AUTOSAR XML (schema 4-2-2)
package /STELLANTIS/EPT/ASWCs
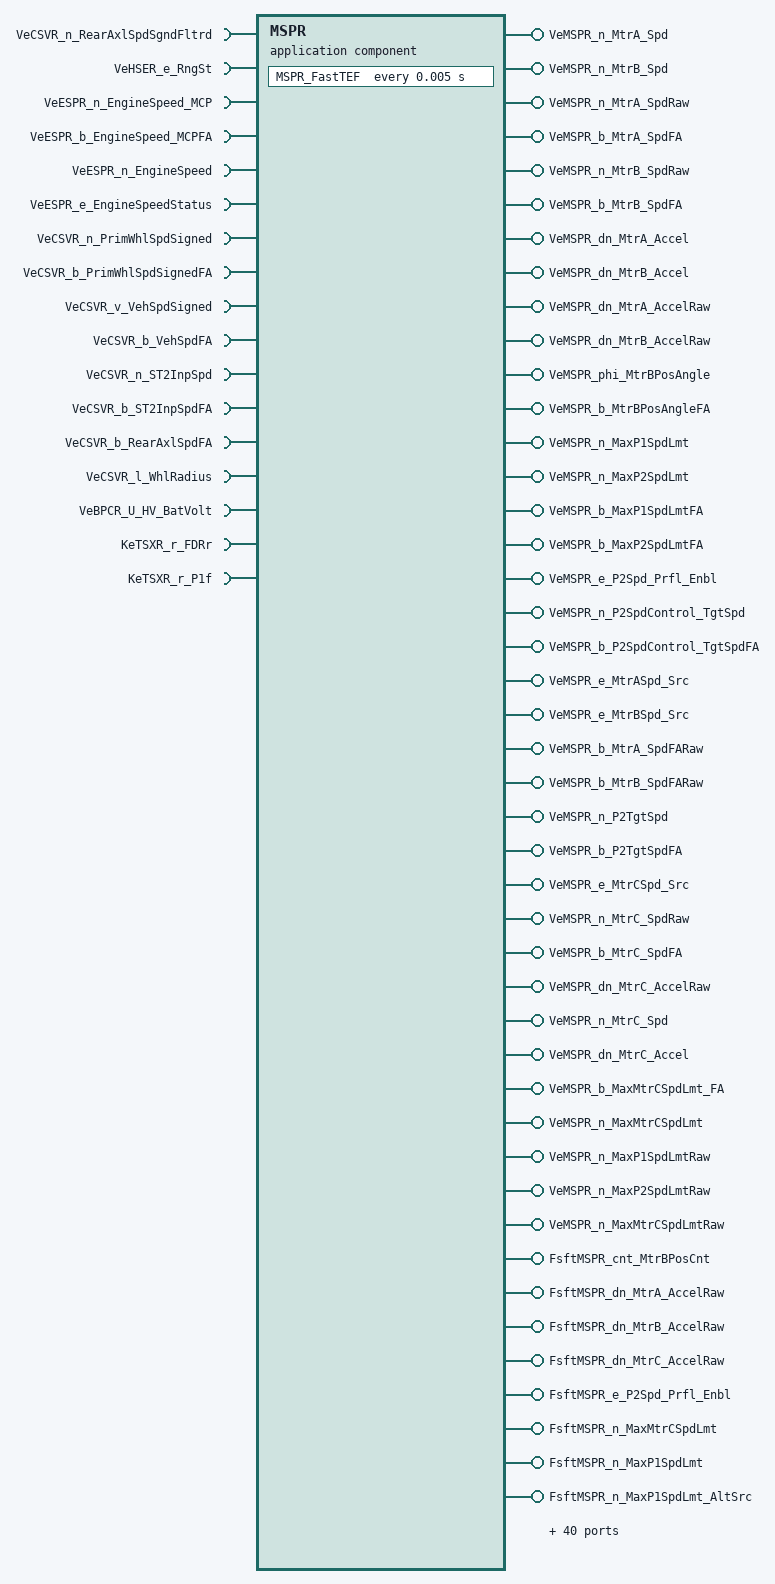
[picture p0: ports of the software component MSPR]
  application sw component type MSPR
    15 x require port:
      VeCSVR_n_RearAxlSpdSgndFltrd: nonqueued-receiver-com-spec{data-element=Value, init-value=0}, required-interface=VeCSVR_n_RearAxlSpdSgndFltrd
      VeHSER_e_RngSt: nonqueued-receiver-com-spec{data-element=Value, init-value=CeHSER_e_Init}, required-interface=VeHSER_e_RngSt
      VeESPR_n_EngineSpeed_MCP: nonqueued-receiver-com-spec{data-element=Value, init-value=0}, required-interface=VeESPR_n_EngineSpeed_MCP
      VeESPR_b_EngineSpeed_MCPFA: nonqueued-receiver-com-spec{data-element=Value, init-value=0}, required-interface=VeESPR_b_EngineSpeed_MCPFA
      VeESPR_n_EngineSpeed: nonqueued-receiver-com-spec{data-element=Value, init-value=0}, required-interface=VeESPR_n_EngineSpeed
      VeESPR_e_EngineSpeedStatus: nonqueued-receiver-com-spec{data-element=Value, init-value=CeESPR_e_EngSpdNormal}, required-interface=VeESPR_e_EngineSpeedStatus
      VeCSVR_n_PrimWhlSpdSigned: nonqueued-receiver-com-spec{data-element=Value, init-value=0}, required-interface=VeCSVR_n_PrimWhlSpdSigned
      VeCSVR_b_PrimWhlSpdSignedFA: nonqueued-receiver-com-spec{data-element=Value, init-value=0}, required-interface=VeCSVR_b_PrimWhlSpdSignedFA
      VeCSVR_v_VehSpdSigned: nonqueued-receiver-com-spec{data-element=Value, init-value=0}, required-interface=VeCSVR_v_VehSpdSigned
      VeCSVR_b_VehSpdFA: nonqueued-receiver-com-spec{data-element=Value, init-value=0}, required-interface=VeCSVR_b_VehSpdFA
      VeCSVR_n_ST2InpSpd: nonqueued-receiver-com-spec{data-element=Value, init-value=0}, required-interface=VeCSVR_n_ST2InpSpd
      VeCSVR_b_ST2InpSpdFA: nonqueued-receiver-com-spec{data-element=Value, init-value=0}, required-interface=VeCSVR_b_ST2InpSpdFA
      VeCSVR_b_RearAxlSpdFA: nonqueued-receiver-com-spec{data-element=Value, init-value=0}, required-interface=VeCSVR_b_RearAxlSpdFA
      VeCSVR_l_WhlRadius: nonqueued-receiver-com-spec{data-element=Value, init-value=0}, required-interface=VeCSVR_l_WhlRadius
      VeBPCR_U_HV_BatVolt: nonqueued-receiver-com-spec{data-element=Value, init-value=0}, required-interface=VeBPCR_U_HV_BatVolt
    84 x provide port:
      VeMSPR_n_MtrA_Spd: nonqueued-sender-com-spec{data-element=Value, init-value=0}, provided-interface=VeMSPR_n_MtrA_Spd
      VeMSPR_n_MtrB_Spd: nonqueued-sender-com-spec{data-element=Value, init-value=0}, provided-interface=VeMSPR_n_MtrB_Spd
      VeMSPR_n_MtrA_SpdRaw: nonqueued-sender-com-spec{data-element=Value, init-value=0}, provided-interface=VeMSPR_n_MtrA_SpdRaw
      VeMSPR_b_MtrA_SpdFA: nonqueued-sender-com-spec{data-element=Value, init-value=0}, provided-interface=VeMSPR_b_MtrA_SpdFA
      VeMSPR_n_MtrB_SpdRaw: nonqueued-sender-com-spec{data-element=Value, init-value=0}, provided-interface=VeMSPR_n_MtrB_SpdRaw
      VeMSPR_b_MtrB_SpdFA: nonqueued-sender-com-spec{data-element=Value, init-value=0}, provided-interface=VeMSPR_b_MtrB_SpdFA
      VeMSPR_dn_MtrA_Accel: nonqueued-sender-com-spec{data-element=Value, init-value=0}, provided-interface=VeMSPR_dn_MtrA_Accel
      VeMSPR_dn_MtrB_Accel: nonqueued-sender-com-spec{data-element=Value, init-value=0}, provided-interface=VeMSPR_dn_MtrB_Accel
      VeMSPR_dn_MtrA_AccelRaw: nonqueued-sender-com-spec{data-element=Value, init-value=0}, provided-interface=VeMSPR_dn_MtrA_AccelRaw
      VeMSPR_dn_MtrB_AccelRaw: nonqueued-sender-com-spec{data-element=Value, init-value=0}, provided-interface=VeMSPR_dn_MtrB_AccelRaw
      VeMSPR_phi_MtrBPosAngle: nonqueued-sender-com-spec{data-element=Value, init-value=0}, provided-interface=VeMSPR_phi_MtrBPosAngle
      VeMSPR_b_MtrBPosAngleFA: nonqueued-sender-com-spec{data-element=Value, init-value=0}, provided-interface=VeMSPR_b_MtrBPosAngleFA
      VeMSPR_n_MaxP1SpdLmt: nonqueued-sender-com-spec{data-element=Value, init-value=0}, provided-interface=VeMSPR_n_MaxP1SpdLmt
      VeMSPR_n_MaxP2SpdLmt: nonqueued-sender-com-spec{data-element=Value, init-value=0}, provided-interface=VeMSPR_n_MaxP2SpdLmt
      VeMSPR_b_MaxP1SpdLmtFA: nonqueued-sender-com-spec{data-element=Value, init-value=0}, provided-interface=VeMSPR_b_MaxP1SpdLmtFA
      VeMSPR_b_MaxP2SpdLmtFA: nonqueued-sender-com-spec{data-element=Value, init-value=0}, provided-interface=VeMSPR_b_MaxP2SpdLmtFA
      VeMSPR_e_P2Spd_Prfl_Enbl: nonqueued-sender-com-spec{data-element=Value, init-value=CeMSPR_e_P2Spd_Prfl_Not_Enbl}, provided-interface=VeMSPR_e_P2Spd_Prfl_Enbl
      VeMSPR_n_P2SpdControl_TgtSpd: nonqueued-sender-com-spec{data-element=Value, init-value=0}, provided-interface=VeMSPR_n_P2SpdControl_TgtSpd
      VeMSPR_b_P2SpdControl_TgtSpdFA: nonqueued-sender-com-spec{data-element=Value, init-value=0}, provided-interface=VeMSPR_b_P2SpdControl_TgtSpdFA
      VeMSPR_e_MtrASpd_Src: nonqueued-sender-com-spec{data-element=Value, init-value=CeMSPR_e_MtrSpSrc_MCP}, provided-interface=VeMSPR_e_MtrASpd_Src
      VeMSPR_e_MtrBSpd_Src: nonqueued-sender-com-spec{data-element=Value, init-value=CeMSPR_e_MtrSpSrc_MCP}, provided-interface=VeMSPR_e_MtrBSpd_Src
      VeMSPR_b_MtrA_SpdFARaw: nonqueued-sender-com-spec{data-element=Value, init-value=0}, provided-interface=VeMSPR_b_MtrA_SpdFARaw
      VeMSPR_b_MtrB_SpdFARaw: nonqueued-sender-com-spec{data-element=Value, init-value=0}, provided-interface=VeMSPR_b_MtrB_SpdFARaw
      VeMSPR_n_P2TgtSpd: nonqueued-sender-com-spec{data-element=Value, init-value=0}, provided-interface=VeMSPR_n_P2TgtSpd
      VeMSPR_b_P2TgtSpdFA: nonqueued-sender-com-spec{data-element=Value, init-value=0}, provided-interface=VeMSPR_b_P2TgtSpdFA
      VeMSPR_e_MtrCSpd_Src: nonqueued-sender-com-spec{data-element=Value, init-value=CeMSPR_e_MtrSpSrc_MCP}, provided-interface=VeMSPR_e_MtrCSpd_Src
      VeMSPR_n_MtrC_SpdRaw: nonqueued-sender-com-spec{data-element=Value, init-value=0}, provided-interface=VeMSPR_n_MtrC_SpdRaw
      VeMSPR_b_MtrC_SpdFA: nonqueued-sender-com-spec{data-element=Value, init-value=0}, provided-interface=VeMSPR_b_MtrC_SpdFA
      VeMSPR_dn_MtrC_AccelRaw: nonqueued-sender-com-spec{data-element=Value, init-value=0}, provided-interface=VeMSPR_dn_MtrC_AccelRaw
      VeMSPR_n_MtrC_Spd: nonqueued-sender-com-spec{data-element=Value, init-value=0}, provided-interface=VeMSPR_n_MtrC_Spd
      VeMSPR_dn_MtrC_Accel: nonqueued-sender-com-spec{data-element=Value, init-value=0}, provided-interface=VeMSPR_dn_MtrC_Accel
      VeMSPR_b_MaxMtrCSpdLmt_FA: nonqueued-sender-com-spec{data-element=Value, init-value=0}, provided-interface=VeMSPR_b_MaxMtrCSpdLmt_FA
      VeMSPR_n_MaxMtrCSpdLmt: nonqueued-sender-com-spec{data-element=Value, init-value=0}, provided-interface=VeMSPR_n_MaxMtrCSpdLmt
      VeMSPR_n_MaxP1SpdLmtRaw: nonqueued-sender-com-spec{data-element=Value, init-value=0}, provided-interface=VeMSPR_n_MaxP1SpdLmtRaw
      VeMSPR_n_MaxP2SpdLmtRaw: nonqueued-sender-com-spec{data-element=Value, init-value=0}, provided-interface=VeMSPR_n_MaxP2SpdLmtRaw
      VeMSPR_n_MaxMtrCSpdLmtRaw: nonqueued-sender-com-spec{data-element=Value, init-value=0}, provided-interface=VeMSPR_n_MaxMtrCSpdLmtRaw
      FsftMSPR_cnt_MtrBPosCnt: server-com-spec=FsftMSPR_cnt_MtrBPosCnt, provided-interface=FsftMSPR_cnt_MtrBPosCnt
      FsftMSPR_dn_MtrA_AccelRaw: server-com-spec=FsftMSPR_dn_MtrA_AccelRaw, provided-interface=FsftMSPR_dn_MtrA_AccelRaw
      FsftMSPR_dn_MtrB_AccelRaw: server-com-spec=FsftMSPR_dn_MtrB_AccelRaw, provided-interface=FsftMSPR_dn_MtrB_AccelRaw
      FsftMSPR_dn_MtrC_AccelRaw: server-com-spec=FsftMSPR_dn_MtrC_AccelRaw, provided-interface=FsftMSPR_dn_MtrC_AccelRaw
      FsftMSPR_e_P2Spd_Prfl_Enbl: server-com-spec=FsftMSPR_e_P2Spd_Prfl_Enbl, provided-interface=FsftMSPR_e_P2Spd_Prfl_Enbl
      FsftMSPR_n_MaxMtrCSpdLmt: server-com-spec=FsftMSPR_n_MaxMtrCSpdLmt, provided-interface=FsftMSPR_n_MaxMtrCSpdLmt
      FsftMSPR_n_MaxP1SpdLmt: server-com-spec=FsftMSPR_n_MaxP1SpdLmt, provided-interface=FsftMSPR_n_MaxP1SpdLmt
      FsftMSPR_n_MaxP1SpdLmt_AltSrc: server-com-spec=FsftMSPR_n_MaxP1SpdLmt_AltSrc, provided-interface=FsftMSPR_n_MaxP1SpdLmt_AltSrc
      FsftMSPR_n_MaxP2SpdLmt: server-com-spec=FsftMSPR_n_MaxP2SpdLmt, provided-interface=FsftMSPR_n_MaxP2SpdLmt
      FsftMSPR_n_MaxP2SpdLmt_AltSrc: server-com-spec=FsftMSPR_n_MaxP2SpdLmt_AltSrc, provided-interface=FsftMSPR_n_MaxP2SpdLmt_AltSrc
      FsftMSPR_n_MtrA_SpdRaw: server-com-spec=FsftMSPR_n_MtrA_SpdRaw, provided-interface=FsftMSPR_n_MtrA_SpdRaw
      FsftMSPR_n_MtrB_SpdRaw: server-com-spec=FsftMSPR_n_MtrB_SpdRaw, provided-interface=FsftMSPR_n_MtrB_SpdRaw
      FsftMSPR_n_MtrC_SpdRaw: server-com-spec=FsftMSPR_n_MtrC_SpdRaw, provided-interface=FsftMSPR_n_MtrC_SpdRaw
      FsftMSPR_n_P2SpdControl_TgtSpd: server-com-spec=FsftMSPR_n_P2SpdControl_TgtSpd, provided-interface=FsftMSPR_n_P2SpdControl_TgtSpd
      FsftMSPR_n_P2TgtSpd: server-com-spec=FsftMSPR_n_P2TgtSpd, provided-interface=FsftMSPR_n_P2TgtSpd
      FsftMSPR_t_MtrBTimeStamp: server-com-spec=FsftMSPR_t_MtrBTimeStamp, provided-interface=FsftMSPR_t_MtrBTimeStamp
      PokeMSPR_b_MCPA_TrqMntrWarn: server-com-spec{operation=PokeMSPR_b_MCPA_TrqMntrWarn, queue-length=1}, provided-interface=PokeMSPR_b_MCPA_TrqMntrWarn
      PokeMSPR_b_MCPB_TrqMntrWarn: server-com-spec{operation=PokeMSPR_b_MCPB_TrqMntrWarn, queue-length=1}, provided-interface=PokeMSPR_b_MCPB_TrqMntrWarn
      PokeMSPR_cnt_MtrBPosCnt: server-com-spec{operation=PokeMSPR_cnt_MtrBPosCnt, queue-length=1}, provided-interface=PokeMSPR_cnt_MtrBPosCnt
      PokeMSPR_dn_MtrA_AccelRaw: server-com-spec{operation=PokeMSPR_dn_MtrA_AccelRaw, queue-length=1}, provided-interface=PokeMSPR_dn_MtrA_AccelRaw
      PokeMSPR_dn_MtrB_AccelRaw: server-com-spec{operation=PokeMSPR_dn_MtrB_AccelRaw, queue-length=1}, provided-interface=PokeMSPR_dn_MtrB_AccelRaw
      PokeMSPR_dn_MtrC_AccelRaw: server-com-spec{operation=PokeMSPR_dn_MtrC_AccelRaw, queue-length=1}, provided-interface=PokeMSPR_dn_MtrC_AccelRaw
      PokeMSPR_e_P2Spd_Prfl_Enbl: server-com-spec{operation=PokeMSPR_e_P2Spd_Prfl_Enbl, queue-length=1}, provided-interface=PokeMSPR_e_P2Spd_Prfl_Enbl
      PokeMSPR_n_MaxMtrCSpdLmt: server-com-spec{operation=PokeMSPR_n_MaxMtrCSpdLmt, queue-length=1}, provided-interface=PokeMSPR_n_MaxMtrCSpdLmt
      PokeMSPR_n_MaxP1SpdLmt: server-com-spec{operation=PokeMSPR_n_MaxP1SpdLmt, queue-length=1}, provided-interface=PokeMSPR_n_MaxP1SpdLmt
      PokeMSPR_n_MaxP1SpdLmt_AltSrc: server-com-spec{operation=PokeMSPR_n_MaxP1SpdLmt_AltSrc, queue-length=1}, provided-interface=PokeMSPR_n_MaxP1SpdLmt_AltSrc
      PokeMSPR_n_MaxP2SpdLmt: server-com-spec{operation=PokeMSPR_n_MaxP2SpdLmt, queue-length=1}, provided-interface=PokeMSPR_n_MaxP2SpdLmt
      PokeMSPR_n_MaxP2SpdLmt_AltSrc: server-com-spec{operation=PokeMSPR_n_MaxP2SpdLmt_AltSrc, queue-length=1}, provided-interface=PokeMSPR_n_MaxP2SpdLmt_AltSrc
      PokeMSPR_n_MtrA_SpdRaw: server-com-spec{operation=PokeMSPR_n_MtrA_SpdRaw, queue-length=1}, provided-interface=PokeMSPR_n_MtrA_SpdRaw
      PokeMSPR_n_MtrB_SpdRaw: server-com-spec{operation=PokeMSPR_n_MtrB_SpdRaw, queue-length=1}, provided-interface=PokeMSPR_n_MtrB_SpdRaw
      PokeMSPR_n_MtrC_SpdRaw: server-com-spec{operation=PokeMSPR_n_MtrC_SpdRaw, queue-length=1}, provided-interface=PokeMSPR_n_MtrC_SpdRaw
      PokeMSPR_n_P2SpdControl_TgtSpd: server-com-spec{operation=PokeMSPR_n_P2SpdControl_TgtSpd, queue-length=1}, provided-interface=PokeMSPR_n_P2SpdControl_TgtSpd
      PokeMSPR_n_P2TgtSpd: server-com-spec{operation=PokeMSPR_n_P2TgtSpd, queue-length=1}, provided-interface=PokeMSPR_n_P2TgtSpd
      PokeMSPR_t_MtrBTimeStamp: server-com-spec{operation=PokeMSPR_t_MtrBTimeStamp, queue-length=1}, provided-interface=PokeMSPR_t_MtrBTimeStamp
      TmotMSPR_b_MCPA_TrqMntrWarn: server-com-spec=TmotMSPR_b_MCPA_TrqMntrWarn, provided-interface=TmotMSPR_b_MCPA_TrqMntrWarn
      TmotMSPR_b_MCPB_TrqMntrWarn: server-com-spec=TmotMSPR_b_MCPB_TrqMntrWarn, provided-interface=TmotMSPR_b_MCPB_TrqMntrWarn
      TmotMSPR_b_MtrA_AccelRaw: server-com-spec=TmotMSPR_b_MtrA_AccelRaw, provided-interface=TmotMSPR_b_MtrA_AccelRaw
      TmotMSPR_b_MtrA_SpdRaw: server-com-spec=TmotMSPR_b_MtrA_SpdRaw, provided-interface=TmotMSPR_b_MtrA_SpdRaw
      TmotMSPR_b_MtrB_AccelRaw: server-com-spec=TmotMSPR_b_MtrB_AccelRaw, provided-interface=TmotMSPR_b_MtrB_AccelRaw
      TmotMSPR_b_MtrB_SpdRaw: server-com-spec=TmotMSPR_b_MtrB_SpdRaw, provided-interface=TmotMSPR_b_MtrB_SpdRaw
      TmotMSPR_b_MtrC_AccelRaw: server-com-spec=TmotMSPR_b_MtrC_AccelRaw, provided-interface=TmotMSPR_b_MtrC_AccelRaw
      TmotMSPR_b_MtrC_SpdRaw: server-com-spec=TmotMSPR_b_MtrC_SpdRaw, provided-interface=TmotMSPR_b_MtrC_SpdRaw
      TmotMSPR_cnt_MtrBPosCnt: server-com-spec=TmotMSPR_cnt_MtrBPosCnt, provided-interface=TmotMSPR_cnt_MtrBPosCnt
      TmotMSPR_n_MaxMtrCSpdLmt: server-com-spec=TmotMSPR_n_MaxMtrCSpdLmt, provided-interface=TmotMSPR_n_MaxMtrCSpdLmt
      TmotMSPR_n_MaxP1SpdLmt: server-com-spec=TmotMSPR_n_MaxP1SpdLmt, provided-interface=TmotMSPR_n_MaxP1SpdLmt
      TmotMSPR_n_MaxP1SpdLmt_AltSrc: server-com-spec=TmotMSPR_n_MaxP1SpdLmt_AltSrc, provided-interface=TmotMSPR_n_MaxP1SpdLmt_AltSrc
      TmotMSPR_n_MaxP2SpdLmt: server-com-spec=TmotMSPR_n_MaxP2SpdLmt, provided-interface=TmotMSPR_n_MaxP2SpdLmt
      TmotMSPR_n_MaxP2SpdLmt_AltSrc: server-com-spec=TmotMSPR_n_MaxP2SpdLmt_AltSrc, provided-interface=TmotMSPR_n_MaxP2SpdLmt_AltSrc
    require port KeTSXR_r_FDRr: parameter-require-com-spec{init-value=KeTSXR_r_FDRr_KeTSXR_r_FDRr:11.1999998092651, parameter=KeTSXR_r_FDRr}, required-interface=KeTSXR_r_FDRr
    require port KeTSXR_r_P1f: parameter-require-com-spec{init-value=KeTSXR_r_P1f_KeTSXR_r_P1f:2.55550003051758, parameter=KeTSXR_r_P1f}, required-interface=KeTSXR_r_P1f
    behavior IB_MSPR: data-type-mapping=msADTtoIDTMapping, handle-termination-and-restart=NO-SUPPORT
      timing event Event_FastTEF: start-on-event=MSPR_FastTEF, period=0.005
      48 x operation invoked event:
        Event_FsftMSPR_cnt_MtrBPosCnt: start-on-event=FsftMSPR_cnt_MtrBPosCnt, operation=FsftMSPR_cnt_MtrBPosCnt.FsftMSPR_cnt_MtrBPosCnt
        Event_FsftMSPR_dn_MtrA_AccelRaw: start-on-event=FsftMSPR_dn_MtrA_AccelRaw, operation=FsftMSPR_dn_MtrA_AccelRaw.FsftMSPR_dn_MtrA_AccelRaw
        Event_FsftMSPR_dn_MtrB_AccelRaw: start-on-event=FsftMSPR_dn_MtrB_AccelRaw, operation=FsftMSPR_dn_MtrB_AccelRaw.FsftMSPR_dn_MtrB_AccelRaw
        Event_FsftMSPR_dn_MtrC_AccelRaw: start-on-event=FsftMSPR_dn_MtrC_AccelRaw, operation=FsftMSPR_dn_MtrC_AccelRaw.FsftMSPR_dn_MtrC_AccelRaw
        Event_FsftMSPR_e_P2Spd_Prfl_Enbl: start-on-event=FsftMSPR_e_P2Spd_Prfl_Enbl, operation=FsftMSPR_e_P2Spd_Prfl_Enbl.FsftMSPR_e_P2Spd_Prfl_Enbl
        Event_FsftMSPR_n_MaxMtrCSpdLmt: start-on-event=FsftMSPR_n_MaxMtrCSpdLmt, operation=FsftMSPR_n_MaxMtrCSpdLmt.FsftMSPR_n_MaxMtrCSpdLmt
        Event_FsftMSPR_n_MaxP1SpdLmt: start-on-event=FsftMSPR_n_MaxP1SpdLmt, operation=FsftMSPR_n_MaxP1SpdLmt.FsftMSPR_n_MaxP1SpdLmt
        Event_FsftMSPR_n_MaxP1SpdLmt_AltSrc: start-on-event=FsftMSPR_n_MaxP1SpdLmt_AltSrc, operation=FsftMSPR_n_MaxP1SpdLmt_AltSrc.FsftMSPR_n_MaxP1SpdLmt_AltSrc
        Event_FsftMSPR_n_MaxP2SpdLmt: start-on-event=FsftMSPR_n_MaxP2SpdLmt, operation=FsftMSPR_n_MaxP2SpdLmt.FsftMSPR_n_MaxP2SpdLmt
        Event_FsftMSPR_n_MaxP2SpdLmt_AltSrc: start-on-event=FsftMSPR_n_MaxP2SpdLmt_AltSrc, operation=FsftMSPR_n_MaxP2SpdLmt_AltSrc.FsftMSPR_n_MaxP2SpdLmt_AltSrc
        Event_FsftMSPR_n_MtrA_SpdRaw: start-on-event=FsftMSPR_n_MtrA_SpdRaw, operation=FsftMSPR_n_MtrA_SpdRaw.FsftMSPR_n_MtrA_SpdRaw
        Event_FsftMSPR_n_MtrB_SpdRaw: start-on-event=FsftMSPR_n_MtrB_SpdRaw, operation=FsftMSPR_n_MtrB_SpdRaw.FsftMSPR_n_MtrB_SpdRaw
        Event_FsftMSPR_n_MtrC_SpdRaw: start-on-event=FsftMSPR_n_MtrC_SpdRaw, operation=FsftMSPR_n_MtrC_SpdRaw.FsftMSPR_n_MtrC_SpdRaw
        Event_FsftMSPR_n_P2SpdControl_TgtSpd: start-on-event=FsftMSPR_n_P2SpdControl_TgtSpd, operation=FsftMSPR_n_P2SpdControl_TgtSpd.FsftMSPR_n_P2SpdControl_TgtSpd
        Event_FsftMSPR_n_P2TgtSpd: start-on-event=FsftMSPR_n_P2TgtSpd, operation=FsftMSPR_n_P2TgtSpd.FsftMSPR_n_P2TgtSpd
        Event_FsftMSPR_t_MtrBTimeStamp: start-on-event=FsftMSPR_t_MtrBTimeStamp, operation=FsftMSPR_t_MtrBTimeStamp.FsftMSPR_t_MtrBTimeStamp
        Event_PokeMSPR_b_MCPA_TrqMntrWarn: start-on-event=PokeMSPR_b_MCPA_TrqMntrWarn, operation=PokeMSPR_b_MCPA_TrqMntrWarn.PokeMSPR_b_MCPA_TrqMntrWarn
        Event_PokeMSPR_b_MCPB_TrqMntrWarn: start-on-event=PokeMSPR_b_MCPB_TrqMntrWarn, operation=PokeMSPR_b_MCPB_TrqMntrWarn.PokeMSPR_b_MCPB_TrqMntrWarn
        Event_PokeMSPR_cnt_MtrBPosCnt: start-on-event=PokeMSPR_cnt_MtrBPosCnt, operation=PokeMSPR_cnt_MtrBPosCnt.PokeMSPR_cnt_MtrBPosCnt
        Event_PokeMSPR_dn_MtrA_AccelRaw: start-on-event=PokeMSPR_dn_MtrA_AccelRaw, operation=PokeMSPR_dn_MtrA_AccelRaw.PokeMSPR_dn_MtrA_AccelRaw
        Event_PokeMSPR_dn_MtrB_AccelRaw: start-on-event=PokeMSPR_dn_MtrB_AccelRaw, operation=PokeMSPR_dn_MtrB_AccelRaw.PokeMSPR_dn_MtrB_AccelRaw
        Event_PokeMSPR_dn_MtrC_AccelRaw: start-on-event=PokeMSPR_dn_MtrC_AccelRaw, operation=PokeMSPR_dn_MtrC_AccelRaw.PokeMSPR_dn_MtrC_AccelRaw
        Event_PokeMSPR_e_P2Spd_Prfl_Enbl: start-on-event=PokeMSPR_e_P2Spd_Prfl_Enbl, operation=PokeMSPR_e_P2Spd_Prfl_Enbl.PokeMSPR_e_P2Spd_Prfl_Enbl
        Event_PokeMSPR_n_MaxMtrCSpdLmt: start-on-event=PokeMSPR_n_MaxMtrCSpdLmt, operation=PokeMSPR_n_MaxMtrCSpdLmt.PokeMSPR_n_MaxMtrCSpdLmt
        Event_PokeMSPR_n_MaxP1SpdLmt: start-on-event=PokeMSPR_n_MaxP1SpdLmt, operation=PokeMSPR_n_MaxP1SpdLmt.PokeMSPR_n_MaxP1SpdLmt
        Event_PokeMSPR_n_MaxP1SpdLmt_AltSrc: start-on-event=PokeMSPR_n_MaxP1SpdLmt_AltSrc, operation=PokeMSPR_n_MaxP1SpdLmt_AltSrc.PokeMSPR_n_MaxP1SpdLmt_AltSrc
        Event_PokeMSPR_n_MaxP2SpdLmt: start-on-event=PokeMSPR_n_MaxP2SpdLmt, operation=PokeMSPR_n_MaxP2SpdLmt.PokeMSPR_n_MaxP2SpdLmt
        Event_PokeMSPR_n_MaxP2SpdLmt_AltSrc: start-on-event=PokeMSPR_n_MaxP2SpdLmt_AltSrc, operation=PokeMSPR_n_MaxP2SpdLmt_AltSrc.PokeMSPR_n_MaxP2SpdLmt_AltSrc
        Event_PokeMSPR_n_MtrA_SpdRaw: start-on-event=PokeMSPR_n_MtrA_SpdRaw, operation=PokeMSPR_n_MtrA_SpdRaw.PokeMSPR_n_MtrA_SpdRaw
        Event_PokeMSPR_n_MtrB_SpdRaw: start-on-event=PokeMSPR_n_MtrB_SpdRaw, operation=PokeMSPR_n_MtrB_SpdRaw.PokeMSPR_n_MtrB_SpdRaw
        Event_PokeMSPR_n_MtrC_SpdRaw: start-on-event=PokeMSPR_n_MtrC_SpdRaw, operation=PokeMSPR_n_MtrC_SpdRaw.PokeMSPR_n_MtrC_SpdRaw
        Event_PokeMSPR_n_P2SpdControl_TgtSpd: start-on-event=PokeMSPR_n_P2SpdControl_TgtSpd, operation=PokeMSPR_n_P2SpdControl_TgtSpd.PokeMSPR_n_P2SpdControl_TgtSpd
        Event_PokeMSPR_n_P2TgtSpd: start-on-event=PokeMSPR_n_P2TgtSpd, operation=PokeMSPR_n_P2TgtSpd.PokeMSPR_n_P2TgtSpd
        Event_PokeMSPR_t_MtrBTimeStamp: start-on-event=PokeMSPR_t_MtrBTimeStamp, operation=PokeMSPR_t_MtrBTimeStamp.PokeMSPR_t_MtrBTimeStamp
        Event_TmotMSPR_b_MCPA_TrqMntrWarn: start-on-event=TmotMSPR_b_MCPA_TrqMntrWarn, operation=TmotMSPR_b_MCPA_TrqMntrWarn.TmotMSPR_b_MCPA_TrqMntrWarn
        Event_TmotMSPR_b_MCPB_TrqMntrWarn: start-on-event=TmotMSPR_b_MCPB_TrqMntrWarn, operation=TmotMSPR_b_MCPB_TrqMntrWarn.TmotMSPR_b_MCPB_TrqMntrWarn
        Event_TmotMSPR_b_MtrA_AccelRaw: start-on-event=TmotMSPR_b_MtrA_AccelRaw, operation=TmotMSPR_b_MtrA_AccelRaw.TmotMSPR_b_MtrA_AccelRaw
        Event_TmotMSPR_b_MtrA_SpdRaw: start-on-event=TmotMSPR_b_MtrA_SpdRaw, operation=TmotMSPR_b_MtrA_SpdRaw.TmotMSPR_b_MtrA_SpdRaw
        Event_TmotMSPR_b_MtrB_AccelRaw: start-on-event=TmotMSPR_b_MtrB_AccelRaw, operation=TmotMSPR_b_MtrB_AccelRaw.TmotMSPR_b_MtrB_AccelRaw
        Event_TmotMSPR_b_MtrB_SpdRaw: start-on-event=TmotMSPR_b_MtrB_SpdRaw, operation=TmotMSPR_b_MtrB_SpdRaw.TmotMSPR_b_MtrB_SpdRaw
        Event_TmotMSPR_b_MtrC_AccelRaw: start-on-event=TmotMSPR_b_MtrC_AccelRaw, operation=TmotMSPR_b_MtrC_AccelRaw.TmotMSPR_b_MtrC_AccelRaw
        Event_TmotMSPR_b_MtrC_SpdRaw: start-on-event=TmotMSPR_b_MtrC_SpdRaw, operation=TmotMSPR_b_MtrC_SpdRaw.TmotMSPR_b_MtrC_SpdRaw
        Event_TmotMSPR_cnt_MtrBPosCnt: start-on-event=TmotMSPR_cnt_MtrBPosCnt, operation=TmotMSPR_cnt_MtrBPosCnt.TmotMSPR_cnt_MtrBPosCnt
        Event_TmotMSPR_n_MaxMtrCSpdLmt: start-on-event=TmotMSPR_n_MaxMtrCSpdLmt, operation=TmotMSPR_n_MaxMtrCSpdLmt.TmotMSPR_n_MaxMtrCSpdLmt
        Event_TmotMSPR_n_MaxP1SpdLmt: start-on-event=TmotMSPR_n_MaxP1SpdLmt, operation=TmotMSPR_n_MaxP1SpdLmt.TmotMSPR_n_MaxP1SpdLmt
        Event_TmotMSPR_n_MaxP1SpdLmt_AltSrc: start-on-event=TmotMSPR_n_MaxP1SpdLmt_AltSrc, operation=TmotMSPR_n_MaxP1SpdLmt_AltSrc.TmotMSPR_n_MaxP1SpdLmt_AltSrc
        Event_TmotMSPR_n_MaxP2SpdLmt: start-on-event=TmotMSPR_n_MaxP2SpdLmt, operation=TmotMSPR_n_MaxP2SpdLmt.TmotMSPR_n_MaxP2SpdLmt
        Event_TmotMSPR_n_MaxP2SpdLmt_AltSrc: start-on-event=TmotMSPR_n_MaxP2SpdLmt_AltSrc, operation=TmotMSPR_n_MaxP2SpdLmt_AltSrc.TmotMSPR_n_MaxP2SpdLmt_AltSrc
      init event Event_MSPR_ac_Init: start-on-event=MSPR_ac_Init
      init event Event_PUP: start-on-event=MSPR_PUP
      init event Event_PwrOn: start-on-event=MSPR_PwrOn
      explicit-inter-runnable-variables:
        40 x data, all with category=VALUE, sw-calibration-access=READ-ONLY:
          VeMSPR_b_MtrA_SpdRawSgnl_Rcvd_write_IRV: type=Boolean, init-value=0
          VeMSPR_b_MtrA_AccelRaw_Rcvd_write_IRV: type=Boolean, init-value=0
          VeMSPR_dn_MtrA_AccelRaw_write_IRV: type=Float, init-value=0
          VeMSPR_b_MtrA_AccelRawFA_write_IRV: type=Boolean, init-value=0
          VeMSPR_b_MtrA_SpdRawFA_write_IRV: type=Boolean, init-value=0
          VeMSPR_n_MtrB_SpdRaw_Init_write_IRV: type=Float, init-value=0
          VeMSPR_b_MtrB_AccelRaw_Rcvd_write_IRV: type=Boolean, init-value=0
          VeMSPR_dn_MtrB_AccelRaw_write_IRV: type=Float, init-value=0
          VeMSPR_b_MtrB_AccelRawFA_write_IRV: type=Boolean, init-value=0
          VeMSPR_b_MtrB_SpdRawFA_write_IRV: type=Boolean, init-value=0
          VeMSPR_cnt_MtrBPosCntSgnl_Rcvd_write_IRV: type=Boolean, init-value=0
          VeMSPR_cnt_MtrBPosCnt_init_write_IRV: type=Float, init-value=0
          VeMSPR_n_MaxP1SpdLmt_AltSrcSgnl_Rcvd_write_IRV: type=Boolean, init-value=0
          VeMSPR_n_MaxP1SpdLmt_AltSrc_Init_write_IRV: type=Float, init-value=0
          VeMSPR_n_MaxP2SpdLmt_AltSrcSgnl_Rcvd_write_IRV: type=Boolean, init-value=0
          VeMSPR_n_MaxP2SpdLmt_AltSrc_Init_write_IRV: type=Float, init-value=0
          VeMSPR_b_MaxP1SpdLmtFA_write_IRV: type=Boolean, init-value=0
          VeMSPR_b_MaxP1SpdLmt_AltSrcFA_write_IRV: type=Boolean, init-value=0
          VeMSPR_b_MaxP2SpdLmtFA_write_IRV: type=Boolean, init-value=0
          VeMSPR_b_MaxP2SpdLmt_AltSrcFA_write_IRV: type=Boolean, init-value=0
          VeMSPR_n_MaxP2SpdLmtSgnl_Rcvd_write_IRV: type=Boolean, init-value=0
          VeMSPR_n_MaxP2SpdLmt_Init_write_IRV: type=Float, init-value=0
          VeMSPR_n_MaxP1SpdLmt_Init_write_IRV: type=Float, init-value=0
          VeMSPR_n_MaxP1SpdLmtSgnl_Rcvd_write_IRV: type=Boolean, init-value=0
          VeMSPR_n_MtrA_SpdRaw_Init_write_IRV: type=Float, init-value=0
          VeMSPR_b_MtrB_SpdRawSgnl_Rcvd_write_IRV: type=Boolean, init-value=0
          VeMSPR_dn_MtrC_AccelRaw_write_IRV: type=Float, init-value=0
          VeMSPR_b_MtrC_SpdRawFA_write_IRV: type=Boolean, init-value=0
          VeMSPR_n_MtrC_SpdRaw_Init_write_IRV: type=Float, init-value=0
          VeMSPR_b_MtrC_SpdRawSgnl_Rcvd_write_IRV: type=Boolean, init-value=0
          VeMSPR_b_MtrC_AccelRawFA_write_IRV: type=Boolean, init-value=0
          VeMSPR_b_MaxMtrCSpdLmtFA_write_IRV: type=Boolean, init-value=0
          VeMSPR_n_MaxMtrCSpdLmt_Init_write_IRV: type=Float, init-value=0
          VeMSPR_b_MaxMtrCSpdLmtSgnl_Rcvd_write_IRV: type=Boolean, init-value=0
          VeMSPR_b_MtrBPosCntFA_write_IRV: type=Boolean, init-value=0
          VeMSPR_e_P2Spd_Prfl_Enbl_write_IRV: type=TeMSPR_e_P2Spd_Prfl_Enbl, init-value=CeMSPR_e_P2Spd_Prfl_Not_Enbl
          VeMSPR_n_P2SpdControl_TgtSpd_Init_write_IRV: type=Float, init-value=0
          VeMSPR_b_P2SpdControl_TgtSpdFA_write_IRV: type=Boolean, init-value=0
          VeMSPR_n_P2TgtSpd_Init_write_IRV: type=Float, init-value=0
          VeMSPR_b_P2TgtSpdFA_write_IRV: type=Boolean, init-value=0
      52 x runnable:
        MSPR_ac_Init
          data-send-points:
            4 x access:
              OUT_VeMSPR_e_P2Spd_Prfl_Enbl_Value: accessed-variable=VeMSPR_e_P2Spd_Prfl_Enbl.Value
              OUT_VeMSPR_e_MtrASpd_Src_Value: accessed-variable=VeMSPR_e_MtrASpd_Src.Value
              OUT_VeMSPR_e_MtrBSpd_Src_Value: accessed-variable=VeMSPR_e_MtrBSpd_Src.Value
              OUT_VeMSPR_e_MtrCSpd_Src_Value: accessed-variable=VeMSPR_e_MtrCSpd_Src.Value
        MSPR_PUP
          data-send-points:
            9 x access:
              OUT_VeMSPR_n_MtrB_Spd_Value: accessed-variable=VeMSPR_n_MtrB_Spd.Value
              OUT_VeMSPR_n_MtrA_Spd_Value: accessed-variable=VeMSPR_n_MtrA_Spd.Value
              OUT_VeMSPR_dn_MtrB_Accel_Value: accessed-variable=VeMSPR_dn_MtrB_Accel.Value
              OUT_VeMSPR_dn_MtrA_Accel_Value: accessed-variable=VeMSPR_dn_MtrA_Accel.Value
              OUT_VeMSPR_dn_MtrC_Accel_Value: accessed-variable=VeMSPR_dn_MtrC_Accel.Value
              OUT_VeMSPR_n_MtrC_Spd_Value: accessed-variable=VeMSPR_n_MtrC_Spd.Value
              OUT_VeMSPR_n_MaxP2SpdLmtRaw_Value: accessed-variable=VeMSPR_n_MaxP2SpdLmtRaw.Value
              OUT_VeMSPR_n_MaxP1SpdLmtRaw_Value: accessed-variable=VeMSPR_n_MaxP1SpdLmtRaw.Value
              OUT_VeMSPR_n_MaxMtrCSpdLmtRaw_Value: accessed-variable=VeMSPR_n_MaxMtrCSpdLmtRaw.Value
          written-local-variables:
            37 x access:
              WV_VeMSPR_b_MaxMtrCSpdLmtFA_write_IRV: accessed-variable=VeMSPR_b_MaxMtrCSpdLmtFA_write_IRV
              WV_VeMSPR_b_MaxMtrCSpdLmtSgnl_Rcvd_write_IRV: accessed-variable=VeMSPR_b_MaxMtrCSpdLmtSgnl_Rcvd_write_IRV
              WV_VeMSPR_b_MaxP1SpdLmt_AltSrcFA_write_IRV: accessed-variable=VeMSPR_b_MaxP1SpdLmt_AltSrcFA_write_IRV
              WV_VeMSPR_b_MaxP1SpdLmtFA_write_IRV: accessed-variable=VeMSPR_b_MaxP1SpdLmtFA_write_IRV
              WV_VeMSPR_n_MaxP1SpdLmt_AltSrcSgnl_Rcvd_write_IRV: accessed-variable=VeMSPR_n_MaxP1SpdLmt_AltSrcSgnl_Rcvd_write_IRV
              WV_VeMSPR_n_MaxP1SpdLmtSgnl_Rcvd_write_IRV: accessed-variable=VeMSPR_n_MaxP1SpdLmtSgnl_Rcvd_write_IRV
              WV_VeMSPR_b_MaxP2SpdLmt_AltSrcFA_write_IRV: accessed-variable=VeMSPR_b_MaxP2SpdLmt_AltSrcFA_write_IRV
              WV_VeMSPR_b_MaxP2SpdLmtFA_write_IRV: accessed-variable=VeMSPR_b_MaxP2SpdLmtFA_write_IRV
              WV_VeMSPR_n_MaxP2SpdLmt_AltSrcSgnl_Rcvd_write_IRV: accessed-variable=VeMSPR_n_MaxP2SpdLmt_AltSrcSgnl_Rcvd_write_IRV
              WV_VeMSPR_n_MaxP2SpdLmtSgnl_Rcvd_write_IRV: accessed-variable=VeMSPR_n_MaxP2SpdLmtSgnl_Rcvd_write_IRV
              WV_VeMSPR_b_MtrA_AccelRawFA_write_IRV: accessed-variable=VeMSPR_b_MtrA_AccelRawFA_write_IRV
              WV_VeMSPR_b_MtrA_SpdRawFA_write_IRV: accessed-variable=VeMSPR_b_MtrA_SpdRawFA_write_IRV
              WV_VeMSPR_b_MtrA_SpdRawSgnl_Rcvd_write_IRV: accessed-variable=VeMSPR_b_MtrA_SpdRawSgnl_Rcvd_write_IRV
              WV_VeMSPR_b_MtrBPosCntFA_write_IRV: accessed-variable=VeMSPR_b_MtrBPosCntFA_write_IRV
              WV_VeMSPR_b_MtrB_AccelRawFA_write_IRV: accessed-variable=VeMSPR_b_MtrB_AccelRawFA_write_IRV
              WV_VeMSPR_b_MtrB_SpdRawFA_write_IRV: accessed-variable=VeMSPR_b_MtrB_SpdRawFA_write_IRV
              WV_VeMSPR_b_MtrB_SpdRawSgnl_Rcvd_write_IRV: accessed-variable=VeMSPR_b_MtrB_SpdRawSgnl_Rcvd_write_IRV
              WV_VeMSPR_b_MtrC_AccelRawFA_write_IRV: accessed-variable=VeMSPR_b_MtrC_AccelRawFA_write_IRV
              WV_VeMSPR_b_MtrC_SpdRawFA_write_IRV: accessed-variable=VeMSPR_b_MtrC_SpdRawFA_write_IRV
              WV_VeMSPR_b_MtrC_SpdRawSgnl_Rcvd_write_IRV: accessed-variable=VeMSPR_b_MtrC_SpdRawSgnl_Rcvd_write_IRV
              WV_VeMSPR_b_P2SpdControl_TgtSpdFA_write_IRV: accessed-variable=VeMSPR_b_P2SpdControl_TgtSpdFA_write_IRV
              WV_VeMSPR_e_P2Spd_Prfl_Enbl_write_IRV: accessed-variable=VeMSPR_e_P2Spd_Prfl_Enbl_write_IRV
              WV_VeMSPR_b_P2TgtSpdFA_write_IRV: accessed-variable=VeMSPR_b_P2TgtSpdFA_write_IRV
              WV_VeMSPR_cnt_MtrBPosCnt_init_write_IRV: accessed-variable=VeMSPR_cnt_MtrBPosCnt_init_write_IRV
              WV_VeMSPR_dn_MtrA_AccelRaw_write_IRV: accessed-variable=VeMSPR_dn_MtrA_AccelRaw_write_IRV
              WV_VeMSPR_dn_MtrB_AccelRaw_write_IRV: accessed-variable=VeMSPR_dn_MtrB_AccelRaw_write_IRV
              WV_VeMSPR_dn_MtrC_AccelRaw_write_IRV: accessed-variable=VeMSPR_dn_MtrC_AccelRaw_write_IRV
              WV_VeMSPR_n_MaxMtrCSpdLmt_Init_write_IRV: accessed-variable=VeMSPR_n_MaxMtrCSpdLmt_Init_write_IRV
              WV_VeMSPR_n_MaxP1SpdLmt_AltSrc_Init_write_IRV: accessed-variable=VeMSPR_n_MaxP1SpdLmt_AltSrc_Init_write_IRV
              WV_VeMSPR_n_MaxP1SpdLmt_Init_write_IRV: accessed-variable=VeMSPR_n_MaxP1SpdLmt_Init_write_IRV
              WV_VeMSPR_n_MaxP2SpdLmt_AltSrc_Init_write_IRV: accessed-variable=VeMSPR_n_MaxP2SpdLmt_AltSrc_Init_write_IRV
              WV_VeMSPR_n_MaxP2SpdLmt_Init_write_IRV: accessed-variable=VeMSPR_n_MaxP2SpdLmt_Init_write_IRV
              WV_VeMSPR_n_MtrA_SpdRaw_Init_write_IRV: accessed-variable=VeMSPR_n_MtrA_SpdRaw_Init_write_IRV
              WV_VeMSPR_n_MtrB_SpdRaw_Init_write_IRV: accessed-variable=VeMSPR_n_MtrB_SpdRaw_Init_write_IRV
              WV_VeMSPR_n_MtrC_SpdRaw_Init_write_IRV: accessed-variable=VeMSPR_n_MtrC_SpdRaw_Init_write_IRV
              WV_VeMSPR_n_P2SpdControl_TgtSpd_Init_write_IRV: accessed-variable=VeMSPR_n_P2SpdControl_TgtSpd_Init_write_IRV
              WV_VeMSPR_n_P2TgtSpd_Init_write_IRV: accessed-variable=VeMSPR_n_P2TgtSpd_Init_write_IRV
        MSPR_FastTEF
          data-receive-point-by-arguments:
            15 x access:
              IN_VeBPCR_U_HV_BatVolt_Value: accessed-variable=VeBPCR_U_HV_BatVolt.Value
              IN_VeCSVR_b_PrimWhlSpdSignedFA_Value: accessed-variable=VeCSVR_b_PrimWhlSpdSignedFA.Value
              IN_VeCSVR_b_RearAxlSpdFA_Value: accessed-variable=VeCSVR_b_RearAxlSpdFA.Value
              IN_VeCSVR_b_ST2InpSpdFA_Value: accessed-variable=VeCSVR_b_ST2InpSpdFA.Value
              IN_VeCSVR_b_VehSpdFA_Value: accessed-variable=VeCSVR_b_VehSpdFA.Value
              IN_VeCSVR_l_WhlRadius_Value: accessed-variable=VeCSVR_l_WhlRadius.Value
              IN_VeCSVR_n_PrimWhlSpdSigned_Value: accessed-variable=VeCSVR_n_PrimWhlSpdSigned.Value
              IN_VeCSVR_n_RearAxlSpdSgndFltrd_Value: accessed-variable=VeCSVR_n_RearAxlSpdSgndFltrd.Value
              IN_VeCSVR_n_ST2InpSpd_Value: accessed-variable=VeCSVR_n_ST2InpSpd.Value
              IN_VeCSVR_v_VehSpdSigned_Value: accessed-variable=VeCSVR_v_VehSpdSigned.Value
              IN_VeESPR_b_EngineSpeed_MCPFA_Value: accessed-variable=VeESPR_b_EngineSpeed_MCPFA.Value
              IN_VeESPR_e_EngineSpeedStatus_Value: accessed-variable=VeESPR_e_EngineSpeedStatus.Value
              IN_VeESPR_n_EngineSpeed_Value: accessed-variable=VeESPR_n_EngineSpeed.Value
              IN_VeESPR_n_EngineSpeed_MCP_Value: accessed-variable=VeESPR_n_EngineSpeed_MCP.Value
              IN_VeHSER_e_RngSt_Value: accessed-variable=VeHSER_e_RngSt.Value
          data-send-points:
            33 x access:
              OUT_VeMSPR_n_MtrB_Spd_Value: accessed-variable=VeMSPR_n_MtrB_Spd.Value
              OUT_VeMSPR_n_MtrA_Spd_Value: accessed-variable=VeMSPR_n_MtrA_Spd.Value
              OUT_VeMSPR_dn_MtrB_Accel_Value: accessed-variable=VeMSPR_dn_MtrB_Accel.Value
              OUT_VeMSPR_dn_MtrA_Accel_Value: accessed-variable=VeMSPR_dn_MtrA_Accel.Value
              OUT_VeMSPR_dn_MtrC_Accel_Value: accessed-variable=VeMSPR_dn_MtrC_Accel.Value
              OUT_VeMSPR_n_MtrC_Spd_Value: accessed-variable=VeMSPR_n_MtrC_Spd.Value
              OUT_VeMSPR_n_MtrA_SpdRaw_Value: accessed-variable=VeMSPR_n_MtrA_SpdRaw.Value
              OUT_VeMSPR_b_MtrA_SpdFA_Value: accessed-variable=VeMSPR_b_MtrA_SpdFA.Value
              OUT_VeMSPR_n_MtrB_SpdRaw_Value: accessed-variable=VeMSPR_n_MtrB_SpdRaw.Value
              OUT_VeMSPR_b_MtrB_SpdFA_Value: accessed-variable=VeMSPR_b_MtrB_SpdFA.Value
              OUT_VeMSPR_dn_MtrA_AccelRaw_Value: accessed-variable=VeMSPR_dn_MtrA_AccelRaw.Value
              OUT_VeMSPR_dn_MtrB_AccelRaw_Value: accessed-variable=VeMSPR_dn_MtrB_AccelRaw.Value
              OUT_VeMSPR_phi_MtrBPosAngle_Value: accessed-variable=VeMSPR_phi_MtrBPosAngle.Value
              OUT_VeMSPR_b_MtrBPosAngleFA_Value: accessed-variable=VeMSPR_b_MtrBPosAngleFA.Value
              OUT_VeMSPR_n_MaxP1SpdLmt_Value: accessed-variable=VeMSPR_n_MaxP1SpdLmt.Value
              OUT_VeMSPR_n_MaxP2SpdLmt_Value: accessed-variable=VeMSPR_n_MaxP2SpdLmt.Value
              OUT_VeMSPR_b_MaxP1SpdLmtFA_Value: accessed-variable=VeMSPR_b_MaxP1SpdLmtFA.Value
              OUT_VeMSPR_b_MaxP2SpdLmtFA_Value: accessed-variable=VeMSPR_b_MaxP2SpdLmtFA.Value
              OUT_VeMSPR_e_P2Spd_Prfl_Enbl_Value: accessed-variable=VeMSPR_e_P2Spd_Prfl_Enbl.Value
              OUT_VeMSPR_n_P2SpdControl_TgtSpd_Value: accessed-variable=VeMSPR_n_P2SpdControl_TgtSpd.Value
              OUT_VeMSPR_b_P2SpdControl_TgtSpdFA_Value: accessed-variable=VeMSPR_b_P2SpdControl_TgtSpdFA.Value
              OUT_VeMSPR_e_MtrASpd_Src_Value: accessed-variable=VeMSPR_e_MtrASpd_Src.Value
              OUT_VeMSPR_e_MtrBSpd_Src_Value: accessed-variable=VeMSPR_e_MtrBSpd_Src.Value
              OUT_VeMSPR_b_MtrA_SpdFARaw_Value: accessed-variable=VeMSPR_b_MtrA_SpdFARaw.Value
              OUT_VeMSPR_b_MtrB_SpdFARaw_Value: accessed-variable=VeMSPR_b_MtrB_SpdFARaw.Value
              OUT_VeMSPR_n_P2TgtSpd_Value: accessed-variable=VeMSPR_n_P2TgtSpd.Value
              OUT_VeMSPR_b_P2TgtSpdFA_Value: accessed-variable=VeMSPR_b_P2TgtSpdFA.Value
              OUT_VeMSPR_e_MtrCSpd_Src_Value: accessed-variable=VeMSPR_e_MtrCSpd_Src.Value
              OUT_VeMSPR_n_MtrC_SpdRaw_Value: accessed-variable=VeMSPR_n_MtrC_SpdRaw.Value
              OUT_VeMSPR_b_MtrC_SpdFA_Value: accessed-variable=VeMSPR_b_MtrC_SpdFA.Value
              OUT_VeMSPR_dn_MtrC_AccelRaw_Value: accessed-variable=VeMSPR_dn_MtrC_AccelRaw.Value
              OUT_VeMSPR_b_MaxMtrCSpdLmt_FA_Value: accessed-variable=VeMSPR_b_MaxMtrCSpdLmt_FA.Value
              OUT_VeMSPR_n_MaxMtrCSpdLmt_Value: accessed-variable=VeMSPR_n_MaxMtrCSpdLmt.Value
          parameter access CALPRM_KeTSXR_r_FDRr_KeTSXR_r_FDRr: accessed-parameter=KeTSXR_r_FDRr.KeTSXR_r_FDRr
          parameter access CALPRM_KeTSXR_r_P1f_KeTSXR_r_P1f: accessed-parameter=KeTSXR_r_P1f.KeTSXR_r_P1f
          read-local-variables:
            33 x access:
              RV_VeMSPR_b_MaxMtrCSpdLmtFA_write_IRV: accessed-variable=VeMSPR_b_MaxMtrCSpdLmtFA_write_IRV
              RV_VeMSPR_b_MaxP1SpdLmtFA_write_IRV: accessed-variable=VeMSPR_b_MaxP1SpdLmtFA_write_IRV
              RV_VeMSPR_b_MaxP1SpdLmt_AltSrcFA_write_IRV: accessed-variable=VeMSPR_b_MaxP1SpdLmt_AltSrcFA_write_IRV
              RV_VeMSPR_b_MaxP2SpdLmtFA_write_IRV: accessed-variable=VeMSPR_b_MaxP2SpdLmtFA_write_IRV
              RV_VeMSPR_b_MaxP2SpdLmt_AltSrcFA_write_IRV: accessed-variable=VeMSPR_b_MaxP2SpdLmt_AltSrcFA_write_IRV
              RV_VeMSPR_b_MtrA_AccelRawFA_write_IRV: accessed-variable=VeMSPR_b_MtrA_AccelRawFA_write_IRV
              RV_VeMSPR_b_MtrA_AccelRaw_Rcvd_write_IRV: accessed-variable=VeMSPR_b_MtrA_AccelRaw_Rcvd_write_IRV
              RV_VeMSPR_b_MtrA_SpdRawFA_write_IRV: accessed-variable=VeMSPR_b_MtrA_SpdRawFA_write_IRV
              RV_VeMSPR_b_MtrA_SpdRawSgnl_Rcvd_write_IRV: accessed-variable=VeMSPR_b_MtrA_SpdRawSgnl_Rcvd_write_IRV
              RV_VeMSPR_b_MtrBPosCntFA_write_IRV: accessed-variable=VeMSPR_b_MtrBPosCntFA_write_IRV
              RV_VeMSPR_b_MtrB_AccelRawFA_write_IRV: accessed-variable=VeMSPR_b_MtrB_AccelRawFA_write_IRV
              RV_VeMSPR_b_MtrB_AccelRaw_Rcvd_write_IRV: accessed-variable=VeMSPR_b_MtrB_AccelRaw_Rcvd_write_IRV
              RV_VeMSPR_b_MtrB_SpdRawFA_write_IRV: accessed-variable=VeMSPR_b_MtrB_SpdRawFA_write_IRV
              RV_VeMSPR_b_MtrB_SpdRawSgnl_Rcvd_write_IRV: accessed-variable=VeMSPR_b_MtrB_SpdRawSgnl_Rcvd_write_IRV
              RV_VeMSPR_b_P2SpdControl_TgtSpdFA_write_IRV: accessed-variable=VeMSPR_b_P2SpdControl_TgtSpdFA_write_IRV
              RV_VeMSPR_b_P2TgtSpdFA_write_IRV: accessed-variable=VeMSPR_b_P2TgtSpdFA_write_IRV
              RV_VeMSPR_cnt_MtrBPosCntSgnl_Rcvd_write_IRV: accessed-variable=VeMSPR_cnt_MtrBPosCntSgnl_Rcvd_write_IRV
              RV_VeMSPR_cnt_MtrBPosCnt_init_write_IRV: accessed-variable=VeMSPR_cnt_MtrBPosCnt_init_write_IRV
              RV_VeMSPR_dn_MtrA_AccelRaw_write_IRV: accessed-variable=VeMSPR_dn_MtrA_AccelRaw_write_IRV
              RV_VeMSPR_dn_MtrB_AccelRaw_write_IRV: accessed-variable=VeMSPR_dn_MtrB_AccelRaw_write_IRV
              RV_VeMSPR_e_P2Spd_Prfl_Enbl_write_IRV: accessed-variable=VeMSPR_e_P2Spd_Prfl_Enbl_write_IRV
              RV_VeMSPR_n_MaxP1SpdLmtSgnl_Rcvd_write_IRV: accessed-variable=VeMSPR_n_MaxP1SpdLmtSgnl_Rcvd_write_IRV
              RV_VeMSPR_n_MaxP1SpdLmt_AltSrcSgnl_Rcvd_write_IRV: accessed-variable=VeMSPR_n_MaxP1SpdLmt_AltSrcSgnl_Rcvd_write_IRV
              RV_VeMSPR_n_MaxP1SpdLmt_AltSrc_Init_write_IRV: accessed-variable=VeMSPR_n_MaxP1SpdLmt_AltSrc_Init_write_IRV
              RV_VeMSPR_n_MaxP1SpdLmt_Init_write_IRV: accessed-variable=VeMSPR_n_MaxP1SpdLmt_Init_write_IRV
              RV_VeMSPR_n_MaxP2SpdLmtSgnl_Rcvd_write_IRV: accessed-variable=VeMSPR_n_MaxP2SpdLmtSgnl_Rcvd_write_IRV
              RV_VeMSPR_n_MaxP2SpdLmt_AltSrcSgnl_Rcvd_write_IRV: accessed-variable=VeMSPR_n_MaxP2SpdLmt_AltSrcSgnl_Rcvd_write_IRV
              RV_VeMSPR_n_MaxP2SpdLmt_AltSrc_Init_write_IRV: accessed-variable=VeMSPR_n_MaxP2SpdLmt_AltSrc_Init_write_IRV
              RV_VeMSPR_n_MaxP2SpdLmt_Init_write_IRV: accessed-variable=VeMSPR_n_MaxP2SpdLmt_Init_write_IRV
              RV_VeMSPR_n_MtrA_SpdRaw_Init_write_IRV: accessed-variable=VeMSPR_n_MtrA_SpdRaw_Init_write_IRV
              RV_VeMSPR_n_MtrB_SpdRaw_Init_write_IRV: accessed-variable=VeMSPR_n_MtrB_SpdRaw_Init_write_IRV
              RV_VeMSPR_n_P2SpdControl_TgtSpd_Init_write_IRV: accessed-variable=VeMSPR_n_P2SpdControl_TgtSpd_Init_write_IRV
              RV_VeMSPR_n_P2TgtSpd_Init_write_IRV: accessed-variable=VeMSPR_n_P2TgtSpd_Init_write_IRV
        MSPR_PwrOn
          data-send-points:
            27 x access:
              OUT_VeMSPR_n_MtrA_SpdRaw_Value: accessed-variable=VeMSPR_n_MtrA_SpdRaw.Value
              OUT_VeMSPR_b_MtrA_SpdFA_Value: accessed-variable=VeMSPR_b_MtrA_SpdFA.Value
              OUT_VeMSPR_n_MtrB_SpdRaw_Value: accessed-variable=VeMSPR_n_MtrB_SpdRaw.Value
              OUT_VeMSPR_b_MtrB_SpdFA_Value: accessed-variable=VeMSPR_b_MtrB_SpdFA.Value
              OUT_VeMSPR_dn_MtrA_AccelRaw_Value: accessed-variable=VeMSPR_dn_MtrA_AccelRaw.Value
              OUT_VeMSPR_dn_MtrB_AccelRaw_Value: accessed-variable=VeMSPR_dn_MtrB_AccelRaw.Value
              OUT_VeMSPR_phi_MtrBPosAngle_Value: accessed-variable=VeMSPR_phi_MtrBPosAngle.Value
              OUT_VeMSPR_b_MtrBPosAngleFA_Value: accessed-variable=VeMSPR_b_MtrBPosAngleFA.Value
              OUT_VeMSPR_n_MaxP1SpdLmt_Value: accessed-variable=VeMSPR_n_MaxP1SpdLmt.Value
              OUT_VeMSPR_n_MaxP2SpdLmt_Value: accessed-variable=VeMSPR_n_MaxP2SpdLmt.Value
              OUT_VeMSPR_b_MaxP1SpdLmtFA_Value: accessed-variable=VeMSPR_b_MaxP1SpdLmtFA.Value
              OUT_VeMSPR_b_MaxP2SpdLmtFA_Value: accessed-variable=VeMSPR_b_MaxP2SpdLmtFA.Value
              OUT_VeMSPR_e_P2Spd_Prfl_Enbl_Value: accessed-variable=VeMSPR_e_P2Spd_Prfl_Enbl.Value
              OUT_VeMSPR_n_P2SpdControl_TgtSpd_Value: accessed-variable=VeMSPR_n_P2SpdControl_TgtSpd.Value
              OUT_VeMSPR_b_P2SpdControl_TgtSpdFA_Value: accessed-variable=VeMSPR_b_P2SpdControl_TgtSpdFA.Value
              OUT_VeMSPR_e_MtrASpd_Src_Value: accessed-variable=VeMSPR_e_MtrASpd_Src.Value
              OUT_VeMSPR_e_MtrBSpd_Src_Value: accessed-variable=VeMSPR_e_MtrBSpd_Src.Value
              OUT_VeMSPR_b_MtrA_SpdFARaw_Value: accessed-variable=VeMSPR_b_MtrA_SpdFARaw.Value
              OUT_VeMSPR_b_MtrB_SpdFARaw_Value: accessed-variable=VeMSPR_b_MtrB_SpdFARaw.Value
              OUT_VeMSPR_n_P2TgtSpd_Value: accessed-variable=VeMSPR_n_P2TgtSpd.Value
              OUT_VeMSPR_b_P2TgtSpdFA_Value: accessed-variable=VeMSPR_b_P2TgtSpdFA.Value
              OUT_VeMSPR_e_MtrCSpd_Src_Value: accessed-variable=VeMSPR_e_MtrCSpd_Src.Value
              OUT_VeMSPR_n_MtrC_SpdRaw_Value: accessed-variable=VeMSPR_n_MtrC_SpdRaw.Value
              OUT_VeMSPR_b_MtrC_SpdFA_Value: accessed-variable=VeMSPR_b_MtrC_SpdFA.Value
              OUT_VeMSPR_dn_MtrC_AccelRaw_Value: accessed-variable=VeMSPR_dn_MtrC_AccelRaw.Value
              OUT_VeMSPR_b_MaxMtrCSpdLmt_FA_Value: accessed-variable=VeMSPR_b_MaxMtrCSpdLmt_FA.Value
              OUT_VeMSPR_n_MaxMtrCSpdLmt_Value: accessed-variable=VeMSPR_n_MaxMtrCSpdLmt.Value
        FsftMSPR_cnt_MtrBPosCnt
          written-local-variables:
            access WV_VeMSPR_b_MtrBPosCntFA_write_IRV: accessed-variable=VeMSPR_b_MtrBPosCntFA_write_IRV
            access WV_VeMSPR_cnt_MtrBPosCntSgnl_Rcvd_write_IRV: accessed-variable=VeMSPR_cnt_MtrBPosCntSgnl_Rcvd_write_IRV
        FsftMSPR_dn_MtrA_AccelRaw
          written-local-variables:
            access WV_VeMSPR_b_MtrA_AccelRawFA_write_IRV: accessed-variable=VeMSPR_b_MtrA_AccelRawFA_write_IRV
            access WV_VeMSPR_b_MtrA_AccelRaw_Rcvd_write_IRV: accessed-variable=VeMSPR_b_MtrA_AccelRaw_Rcvd_write_IRV
            access WV_VeMSPR_dn_MtrA_AccelRaw_write_IRV: accessed-variable=VeMSPR_dn_MtrA_AccelRaw_write_IRV
        FsftMSPR_dn_MtrB_AccelRaw
          written-local-variables:
            access WV_VeMSPR_b_MtrB_AccelRawFA_write_IRV: accessed-variable=VeMSPR_b_MtrB_AccelRawFA_write_IRV
            access WV_VeMSPR_b_MtrB_AccelRaw_Rcvd_write_IRV: accessed-variable=VeMSPR_b_MtrB_AccelRaw_Rcvd_write_IRV
            access WV_VeMSPR_dn_MtrB_AccelRaw_write_IRV: accessed-variable=VeMSPR_dn_MtrB_AccelRaw_write_IRV
        FsftMSPR_dn_MtrC_AccelRaw
        FsftMSPR_e_P2Spd_Prfl_Enbl
          written-local-variables:
            access WV_VeMSPR_e_P2Spd_Prfl_Enbl_write_IRV: accessed-variable=VeMSPR_e_P2Spd_Prfl_Enbl_write_IRV
        FsftMSPR_n_MaxMtrCSpdLmt
          written-local-variables:
            access WV_VeMSPR_b_MaxMtrCSpdLmtFA_write_IRV: accessed-variable=VeMSPR_b_MaxMtrCSpdLmtFA_write_IRV
        FsftMSPR_n_MaxP1SpdLmt
          written-local-variables:
            access WV_VeMSPR_b_MaxP1SpdLmtFA_write_IRV: accessed-variable=VeMSPR_b_MaxP1SpdLmtFA_write_IRV
            access WV_VeMSPR_n_MaxP1SpdLmtSgnl_Rcvd_write_IRV: accessed-variable=VeMSPR_n_MaxP1SpdLmtSgnl_Rcvd_write_IRV
        FsftMSPR_n_MaxP1SpdLmt_AltSrc
          written-local-variables:
            access WV_VeMSPR_b_MaxP1SpdLmt_AltSrcFA_write_IRV: accessed-variable=VeMSPR_b_MaxP1SpdLmt_AltSrcFA_write_IRV
            access WV_VeMSPR_n_MaxP1SpdLmt_AltSrcSgnl_Rcvd_write_IRV: accessed-variable=VeMSPR_n_MaxP1SpdLmt_AltSrcSgnl_Rcvd_write_IRV
        FsftMSPR_n_MaxP2SpdLmt
          written-local-variables:
            access WV_VeMSPR_b_MaxP2SpdLmtFA_write_IRV: accessed-variable=VeMSPR_b_MaxP2SpdLmtFA_write_IRV
            access WV_VeMSPR_n_MaxP2SpdLmtSgnl_Rcvd_write_IRV: accessed-variable=VeMSPR_n_MaxP2SpdLmtSgnl_Rcvd_write_IRV
        FsftMSPR_n_MaxP2SpdLmt_AltSrc
          written-local-variables:
            access WV_VeMSPR_b_MaxP2SpdLmt_AltSrcFA_write_IRV: accessed-variable=VeMSPR_b_MaxP2SpdLmt_AltSrcFA_write_IRV
            access WV_VeMSPR_n_MaxP2SpdLmt_AltSrcSgnl_Rcvd_write_IRV: accessed-variable=VeMSPR_n_MaxP2SpdLmt_AltSrcSgnl_Rcvd_write_IRV
        FsftMSPR_n_MtrA_SpdRaw
          written-local-variables:
            access WV_VeMSPR_b_MtrA_SpdRawFA_write_IRV: accessed-variable=VeMSPR_b_MtrA_SpdRawFA_write_IRV
            access WV_VeMSPR_b_MtrA_SpdRawSgnl_Rcvd_write_IRV: accessed-variable=VeMSPR_b_MtrA_SpdRawSgnl_Rcvd_write_IRV
        FsftMSPR_n_MtrB_SpdRaw
          written-local-variables:
            access WV_VeMSPR_b_MtrB_SpdRawFA_write_IRV: accessed-variable=VeMSPR_b_MtrB_SpdRawFA_write_IRV
            access WV_VeMSPR_b_MtrB_SpdRawSgnl_Rcvd_write_IRV: accessed-variable=VeMSPR_b_MtrB_SpdRawSgnl_Rcvd_write_IRV
        FsftMSPR_n_MtrC_SpdRaw
        FsftMSPR_n_P2SpdControl_TgtSpd
          written-local-variables:
            access WV_VeMSPR_b_P2SpdControl_TgtSpdFA_write_IRV: accessed-variable=VeMSPR_b_P2SpdControl_TgtSpdFA_write_IRV
        FsftMSPR_n_P2TgtSpd
          written-local-variables:
            access WV_VeMSPR_b_P2TgtSpdFA_write_IRV: accessed-variable=VeMSPR_b_P2TgtSpdFA_write_IRV
        FsftMSPR_t_MtrBTimeStamp
        PokeMSPR_b_MCPA_TrqMntrWarn
        PokeMSPR_b_MCPB_TrqMntrWarn
        PokeMSPR_cnt_MtrBPosCnt
          written-local-variables:
            access WV_VeMSPR_b_MtrBPosCntFA_write_IRV: accessed-variable=VeMSPR_b_MtrBPosCntFA_write_IRV
            access WV_VeMSPR_cnt_MtrBPosCntSgnl_Rcvd_write_IRV: accessed-variable=VeMSPR_cnt_MtrBPosCntSgnl_Rcvd_write_IRV
            access WV_VeMSPR_cnt_MtrBPosCnt_init_write_IRV: accessed-variable=VeMSPR_cnt_MtrBPosCnt_init_write_IRV
        PokeMSPR_dn_MtrA_AccelRaw
          written-local-variables:
            access WV_VeMSPR_b_MtrA_AccelRawFA_write_IRV: accessed-variable=VeMSPR_b_MtrA_AccelRawFA_write_IRV
            access WV_VeMSPR_b_MtrA_AccelRaw_Rcvd_write_IRV: accessed-variable=VeMSPR_b_MtrA_AccelRaw_Rcvd_write_IRV
            access WV_VeMSPR_dn_MtrA_AccelRaw_write_IRV: accessed-variable=VeMSPR_dn_MtrA_AccelRaw_write_IRV
        PokeMSPR_dn_MtrB_AccelRaw
          written-local-variables:
            access WV_VeMSPR_b_MtrB_AccelRawFA_write_IRV: accessed-variable=VeMSPR_b_MtrB_AccelRawFA_write_IRV
            access WV_VeMSPR_b_MtrB_AccelRaw_Rcvd_write_IRV: accessed-variable=VeMSPR_b_MtrB_AccelRaw_Rcvd_write_IRV
            access WV_VeMSPR_dn_MtrB_AccelRaw_write_IRV: accessed-variable=VeMSPR_dn_MtrB_AccelRaw_write_IRV
        PokeMSPR_dn_MtrC_AccelRaw
        PokeMSPR_e_P2Spd_Prfl_Enbl
          written-local-variables:
            access WV_VeMSPR_e_P2Spd_Prfl_Enbl_write_IRV: accessed-variable=VeMSPR_e_P2Spd_Prfl_Enbl_write_IRV
        PokeMSPR_n_MaxMtrCSpdLmt
          data-send-points:
            access OUT_VeMSPR_n_MaxMtrCSpdLmtRaw_Value: accessed-variable=VeMSPR_n_MaxMtrCSpdLmtRaw.Value
        PokeMSPR_n_MaxP1SpdLmt
          data-send-points:
            access OUT_VeMSPR_n_MaxP1SpdLmtRaw_Value: accessed-variable=VeMSPR_n_MaxP1SpdLmtRaw.Value
          written-local-variables:
            access WV_VeMSPR_n_MaxP1SpdLmtSgnl_Rcvd_write_IRV: accessed-variable=VeMSPR_n_MaxP1SpdLmtSgnl_Rcvd_write_IRV
            access WV_VeMSPR_n_MaxP1SpdLmt_Init_write_IRV: accessed-variable=VeMSPR_n_MaxP1SpdLmt_Init_write_IRV
        PokeMSPR_n_MaxP1SpdLmt_AltSrc
          written-local-variables:
            access WV_VeMSPR_b_MaxP1SpdLmt_AltSrcFA_write_IRV: accessed-variable=VeMSPR_b_MaxP1SpdLmt_AltSrcFA_write_IRV
            access WV_VeMSPR_n_MaxP1SpdLmt_AltSrcSgnl_Rcvd_write_IRV: accessed-variable=VeMSPR_n_MaxP1SpdLmt_AltSrcSgnl_Rcvd_write_IRV
            access WV_VeMSPR_n_MaxP1SpdLmt_AltSrc_Init_write_IRV: accessed-variable=VeMSPR_n_MaxP1SpdLmt_AltSrc_Init_write_IRV
        PokeMSPR_n_MaxP2SpdLmt
          data-send-points:
            access OUT_VeMSPR_n_MaxP2SpdLmtRaw_Value: accessed-variable=VeMSPR_n_MaxP2SpdLmtRaw.Value
          written-local-variables:
            access WV_VeMSPR_n_MaxP2SpdLmtSgnl_Rcvd_write_IRV: accessed-variable=VeMSPR_n_MaxP2SpdLmtSgnl_Rcvd_write_IRV
            access WV_VeMSPR_n_MaxP2SpdLmt_Init_write_IRV: accessed-variable=VeMSPR_n_MaxP2SpdLmt_Init_write_IRV
        PokeMSPR_n_MaxP2SpdLmt_AltSrc
          written-local-variables:
            access WV_VeMSPR_b_MaxP2SpdLmt_AltSrcFA_write_IRV: accessed-variable=VeMSPR_b_MaxP2SpdLmt_AltSrcFA_write_IRV
            access WV_VeMSPR_n_MaxP2SpdLmt_AltSrcSgnl_Rcvd_write_IRV: accessed-variable=VeMSPR_n_MaxP2SpdLmt_AltSrcSgnl_Rcvd_write_IRV
            access WV_VeMSPR_n_MaxP2SpdLmt_AltSrc_Init_write_IRV: accessed-variable=VeMSPR_n_MaxP2SpdLmt_AltSrc_Init_write_IRV
        PokeMSPR_n_MtrA_SpdRaw
          written-local-variables:
            access WV_VeMSPR_b_MtrA_SpdRawFA_write_IRV: accessed-variable=VeMSPR_b_MtrA_SpdRawFA_write_IRV
            access WV_VeMSPR_b_MtrA_SpdRawSgnl_Rcvd_write_IRV: accessed-variable=VeMSPR_b_MtrA_SpdRawSgnl_Rcvd_write_IRV
            access WV_VeMSPR_n_MtrA_SpdRaw_Init_write_IRV: accessed-variable=VeMSPR_n_MtrA_SpdRaw_Init_write_IRV
        PokeMSPR_n_MtrB_SpdRaw
          written-local-variables:
            access WV_VeMSPR_b_MtrB_SpdRawFA_write_IRV: accessed-variable=VeMSPR_b_MtrB_SpdRawFA_write_IRV
            access WV_VeMSPR_b_MtrB_SpdRawSgnl_Rcvd_write_IRV: accessed-variable=VeMSPR_b_MtrB_SpdRawSgnl_Rcvd_write_IRV
            access WV_VeMSPR_n_MtrB_SpdRaw_Init_write_IRV: accessed-variable=VeMSPR_n_MtrB_SpdRaw_Init_write_IRV
        PokeMSPR_n_MtrC_SpdRaw
        PokeMSPR_n_P2SpdControl_TgtSpd
          written-local-variables:
            access WV_VeMSPR_b_P2SpdControl_TgtSpdFA_write_IRV: accessed-variable=VeMSPR_b_P2SpdControl_TgtSpdFA_write_IRV
            access WV_VeMSPR_n_P2SpdControl_TgtSpd_Init_write_IRV: accessed-variable=VeMSPR_n_P2SpdControl_TgtSpd_Init_write_IRV
        PokeMSPR_n_P2TgtSpd
          written-local-variables:
            access WV_VeMSPR_b_P2TgtSpdFA_write_IRV: accessed-variable=VeMSPR_b_P2TgtSpdFA_write_IRV
            access WV_VeMSPR_n_P2TgtSpd_Init_write_IRV: accessed-variable=VeMSPR_n_P2TgtSpd_Init_write_IRV
        PokeMSPR_t_MtrBTimeStamp
        TmotMSPR_b_MCPA_TrqMntrWarn
        TmotMSPR_b_MCPB_TrqMntrWarn
        TmotMSPR_b_MtrA_AccelRaw
          written-local-variables:
            access WV_VeMSPR_b_MtrA_AccelRaw_Rcvd_write_IRV: accessed-variable=VeMSPR_b_MtrA_AccelRaw_Rcvd_write_IRV
        TmotMSPR_b_MtrA_SpdRaw
          written-local-variables:
            access WV_VeMSPR_b_MtrA_SpdRawSgnl_Rcvd_write_IRV: accessed-variable=VeMSPR_b_MtrA_SpdRawSgnl_Rcvd_write_IRV
        TmotMSPR_b_MtrB_AccelRaw
          written-local-variables:
            access WV_VeMSPR_b_MtrB_AccelRaw_Rcvd_write_IRV: accessed-variable=VeMSPR_b_MtrB_AccelRaw_Rcvd_write_IRV
        TmotMSPR_b_MtrB_SpdRaw
          written-local-variables:
            access WV_VeMSPR_b_MtrB_SpdRawSgnl_Rcvd_write_IRV: accessed-variable=VeMSPR_b_MtrB_SpdRawSgnl_Rcvd_write_IRV
        TmotMSPR_b_MtrC_AccelRaw
        TmotMSPR_b_MtrC_SpdRaw
        TmotMSPR_cnt_MtrBPosCnt
          written-local-variables:
            access WV_VeMSPR_cnt_MtrBPosCntSgnl_Rcvd_write_IRV: accessed-variable=VeMSPR_cnt_MtrBPosCntSgnl_Rcvd_write_IRV
        TmotMSPR_n_MaxMtrCSpdLmt
        TmotMSPR_n_MaxP1SpdLmt
          written-local-variables:
            access WV_VeMSPR_n_MaxP1SpdLmtSgnl_Rcvd_write_IRV: accessed-variable=VeMSPR_n_MaxP1SpdLmtSgnl_Rcvd_write_IRV
        TmotMSPR_n_MaxP1SpdLmt_AltSrc
          written-local-variables:
            access WV_VeMSPR_n_MaxP1SpdLmt_AltSrcSgnl_Rcvd_write_IRV: accessed-variable=VeMSPR_n_MaxP1SpdLmt_AltSrcSgnl_Rcvd_write_IRV
        TmotMSPR_n_MaxP2SpdLmt
          written-local-variables:
            access WV_VeMSPR_n_MaxP2SpdLmtSgnl_Rcvd_write_IRV: accessed-variable=VeMSPR_n_MaxP2SpdLmtSgnl_Rcvd_write_IRV
        TmotMSPR_n_MaxP2SpdLmt_AltSrc
          written-local-variables:
            access WV_VeMSPR_n_MaxP2SpdLmt_AltSrcSgnl_Rcvd_write_IRV: accessed-variable=VeMSPR_n_MaxP2SpdLmt_AltSrcSgnl_Rcvd_write_IRV
      variation point proxy Variant_MSPR_1: category=CONDITION, condition-access=0
